# Espressif register map
File version: 1.0
CPU: Xtensa LX6 1, little endian, no MPU, FPU, 3 interrupt priority bits
Registers are 32-bit, access not given, reset 0x0 unless marked. A register's access mark holds for its fields unless they carry their own. Offsets are from the block's base; lines under a group give offsets from that group; [hi:lo] are bit positions; {n}, {i} and the like mark numbered series; 'fields as' and 'values as' point back to an identical list; <NAME> marks a mode.

## Memory map
0x00000000 SPI size 0x860
0x00000000 I2C size 0x4C0
0x00000000 UHCI size 0x620
0x00000000 TIMG size 0x580
0x00000000 MCPWM size 0x940
0x3FF00000 DPORT size 0x2DE0
0x3FF01000 AES
0x3FF02000 RSA
0x3FF03000 SHA
0x3FF40000 UART size 0x3A0
0x3FF42000 SPI1
0x3FF43000 SPI0
0x3FF44000 GPIO size 0x2E60
0x3FF44F00 GPIO_SD size 0x160
0x3FF45000 FE2
0x3FF46000 FE
0x3FF47000 FRC_TIMER
0x3FF48000 RTCCNTL size 0x6A0
0x3FF48400 RTCIO size 0x660
0x3FF48800 SENS size 0x540
0x3FF48C00 RTC_I2C size 0x160
0x3FF49000 IO_MUX
0x3FF4B000 HINF size 0x1A0
0x3FF4C000 UHCI1
0x3FF4F000 I2S size 0x5A0
0x3FF50000 UART1
0x3FF51000 BT
0x3FF53000 I2C_EXT
0x3FF54000 UHCI0
0x3FF55000 SLCHOST size 0x800
0x3FF56000 RMT size 0x6C0
0x3FF57000 PCNT size 0x5C0
0x3FF58000 SLC size 0xA60
0x3FF59000 LEDC size 0xCC0
0x3FF5A000 EFUSE size 0x920
0x3FF5B000 SPI_ENCRYPT
0x3FF5CC00 NRX
0x3FF5D000 BB
0x3FF5E000 PWM
0x3FF5F000 TIMERGROUP0
0x3FF60000 TIMERGROUP1
0x3FF61000 RTCMEM0
0x3FF62000 RTCMEM1
0x3FF63000 RTCMEM2
0x3FF64000 SPI2
0x3FF65000 SPI3
0x3FF66000 APB_CTRL size 0x220
0x3FF66000 SYSCON size 0x220
0x3FF67000 I2C1_EXT
0x3FF68000 SDMMC
0x3FF69000 EMAC
0x3FF6B000 CAN
0x3FF6C000 PWM1
0x3FF6D000 I2S1
0x3FF6E000 UART2
0x3FF6F000 PWM2
0x3FF70000 PWM3

## HINF
Base 0x3FF4B000
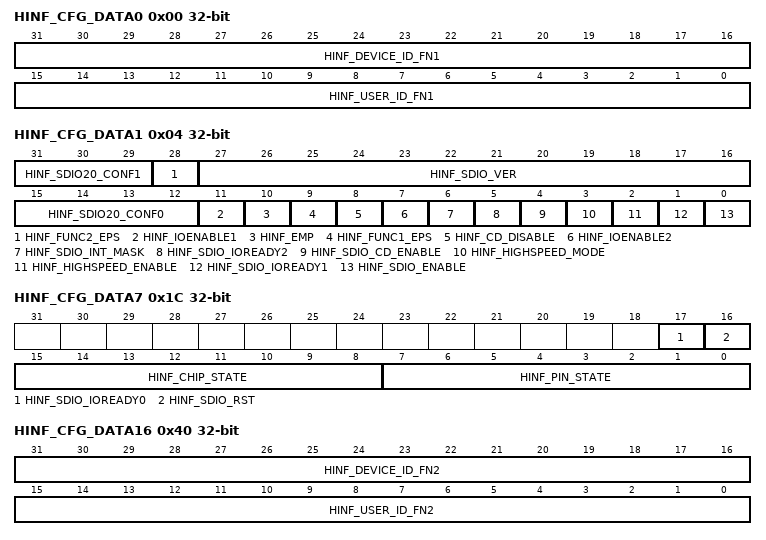
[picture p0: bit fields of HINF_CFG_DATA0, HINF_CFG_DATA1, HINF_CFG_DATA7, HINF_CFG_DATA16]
0x00 HINF_CFG_DATA0
  [31:16] HINF_DEVICE_ID_FN1, [15:0] HINF_USER_ID_FN1
0x04 HINF_CFG_DATA1
  [31:29] HINF_SDIO20_CONF1, [28] HINF_FUNC2_EPS, [27:16] HINF_SDIO_VER, [15:12] HINF_SDIO20_CONF0, [11] HINF_IOENABLE1, [10] HINF_EMP, [9] HINF_FUNC1_EPS, [8] HINF_CD_DISABLE, [7] HINF_IOENABLE2, [6] HINF_SDIO_INT_MASK, [5] HINF_SDIO_IOREADY2, [4] HINF_SDIO_CD_ENABLE, [3] HINF_HIGHSPEED_MODE, [2] HINF_HIGHSPEED_ENABLE, [1] HINF_SDIO_IOREADY1, [0] HINF_SDIO_ENABLE
0x1C HINF_CFG_DATA7
  [17] HINF_SDIO_IOREADY0, [16] HINF_SDIO_RST, [15:8] HINF_CHIP_STATE, [7:0] HINF_PIN_STATE
{0x20+4i} HINF_CIS_CONF{i} (i=0..7)
  [31:0] HINF_CIS_CONF_W{i}
0x40 HINF_CFG_DATA16
  [31:16] HINF_DEVICE_ID_FN2, [15:0] HINF_USER_ID_FN2
0xFC HINF_DATE
  [31:0] HINF_SDIO_DATE

## I2C
Base 0x00000000
0x00 I2C_SCL_LOW_PERIOD
  [13:0] I2C_SCL_LOW_PERIOD
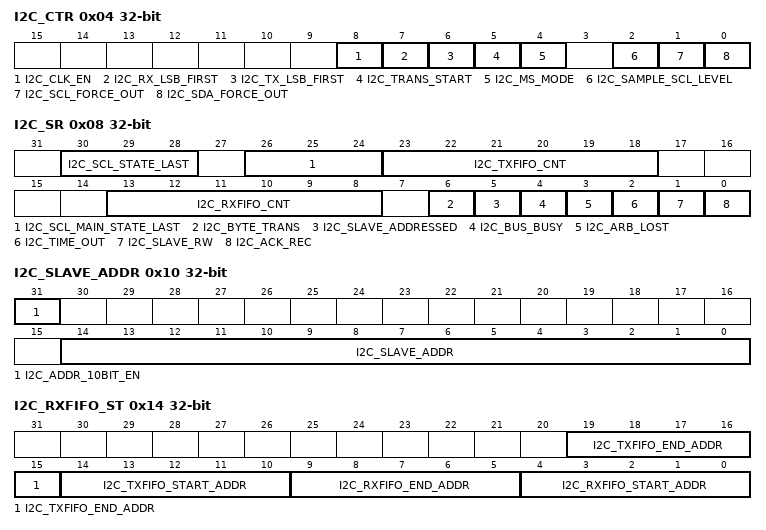
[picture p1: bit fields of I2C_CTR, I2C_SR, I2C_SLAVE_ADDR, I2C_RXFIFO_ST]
0x04 I2C_CTR
  [8] I2C_CLK_EN, [7] I2C_RX_LSB_FIRST, [6] I2C_TX_LSB_FIRST, [5] I2C_TRANS_START, [4] I2C_MS_MODE, [2] I2C_SAMPLE_SCL_LEVEL, [1] I2C_SCL_FORCE_OUT, [0] I2C_SDA_FORCE_OUT
0x08 I2C_SR
  [30:28] I2C_SCL_STATE_LAST, [26:24] I2C_SCL_MAIN_STATE_LAST, [23:18] I2C_TXFIFO_CNT, [13:8] I2C_RXFIFO_CNT, [6] I2C_BYTE_TRANS, [5] I2C_SLAVE_ADDRESSED, [4] I2C_BUS_BUSY, [3] I2C_ARB_LOST, [2] I2C_TIME_OUT, [1] I2C_SLAVE_RW, [0] I2C_ACK_REC
0x0C I2C_TO
  [19:0] I2C_TIME_OUT_REG
0x10 I2C_SLAVE_ADDR
  [31] I2C_ADDR_10BIT_EN, [14:0] I2C_SLAVE_ADDR
0x14 I2C_RXFIFO_ST
  [19:15] I2C_TXFIFO_END_ADDR, [14:10] I2C_TXFIFO_START_ADDR, [9:5] I2C_RXFIFO_END_ADDR, [4:0] I2C_RXFIFO_START_ADDR
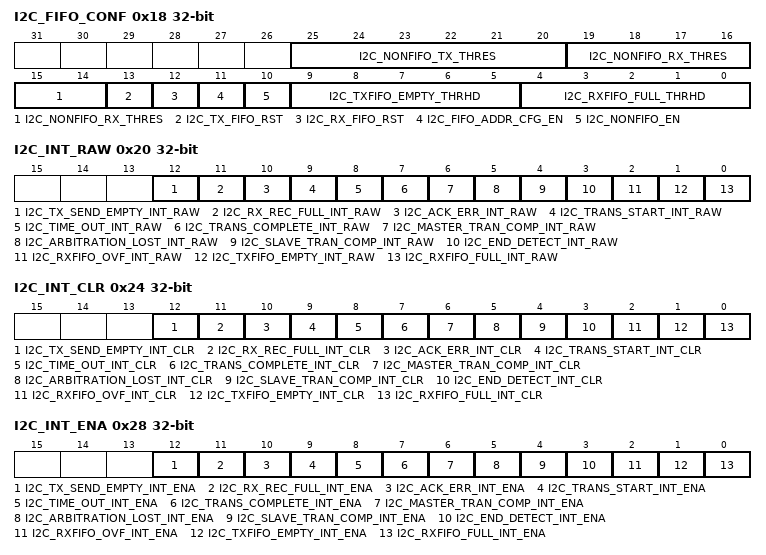
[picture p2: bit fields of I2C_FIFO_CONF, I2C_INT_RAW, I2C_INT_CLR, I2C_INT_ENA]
0x18 I2C_FIFO_CONF
  [25:20] I2C_NONFIFO_TX_THRES, [19:14] I2C_NONFIFO_RX_THRES, [13] I2C_TX_FIFO_RST, [12] I2C_RX_FIFO_RST, [11] I2C_FIFO_ADDR_CFG_EN, [10] I2C_NONFIFO_EN, [9:5] I2C_TXFIFO_EMPTY_THRHD, [4:0] I2C_RXFIFO_FULL_THRHD
0x1C I2C_DATA
  [7:0] I2C_FIFO_RDATA
0x20 I2C_INT_RAW
  [12] I2C_TX_SEND_EMPTY_INT_RAW, [11] I2C_RX_REC_FULL_INT_RAW, [10] I2C_ACK_ERR_INT_RAW, [9] I2C_TRANS_START_INT_RAW, [8] I2C_TIME_OUT_INT_RAW, [7] I2C_TRANS_COMPLETE_INT_RAW, [6] I2C_MASTER_TRAN_COMP_INT_RAW, [5] I2C_ARBITRATION_LOST_INT_RAW, [4] I2C_SLAVE_TRAN_COMP_INT_RAW, [3] I2C_END_DETECT_INT_RAW, [2] I2C_RXFIFO_OVF_INT_RAW, [1] I2C_TXFIFO_EMPTY_INT_RAW, [0] I2C_RXFIFO_FULL_INT_RAW
0x24 I2C_INT_CLR
  [12] I2C_TX_SEND_EMPTY_INT_CLR, [11] I2C_RX_REC_FULL_INT_CLR, [10] I2C_ACK_ERR_INT_CLR, [9] I2C_TRANS_START_INT_CLR, [8] I2C_TIME_OUT_INT_CLR, [7] I2C_TRANS_COMPLETE_INT_CLR, [6] I2C_MASTER_TRAN_COMP_INT_CLR, [5] I2C_ARBITRATION_LOST_INT_CLR, [4] I2C_SLAVE_TRAN_COMP_INT_CLR, [3] I2C_END_DETECT_INT_CLR, [2] I2C_RXFIFO_OVF_INT_CLR, [1] I2C_TXFIFO_EMPTY_INT_CLR, [0] I2C_RXFIFO_FULL_INT_CLR
0x28 I2C_INT_ENA
  [12] I2C_TX_SEND_EMPTY_INT_ENA, [11] I2C_RX_REC_FULL_INT_ENA, [10] I2C_ACK_ERR_INT_ENA, [9] I2C_TRANS_START_INT_ENA, [8] I2C_TIME_OUT_INT_ENA, [7] I2C_TRANS_COMPLETE_INT_ENA, [6] I2C_MASTER_TRAN_COMP_INT_ENA, [5] I2C_ARBITRATION_LOST_INT_ENA, [4] I2C_SLAVE_TRAN_COMP_INT_ENA, [3] I2C_END_DETECT_INT_ENA, [2] I2C_RXFIFO_OVF_INT_ENA, [1] I2C_TXFIFO_EMPTY_INT_ENA, [0] I2C_RXFIFO_FULL_INT_ENA
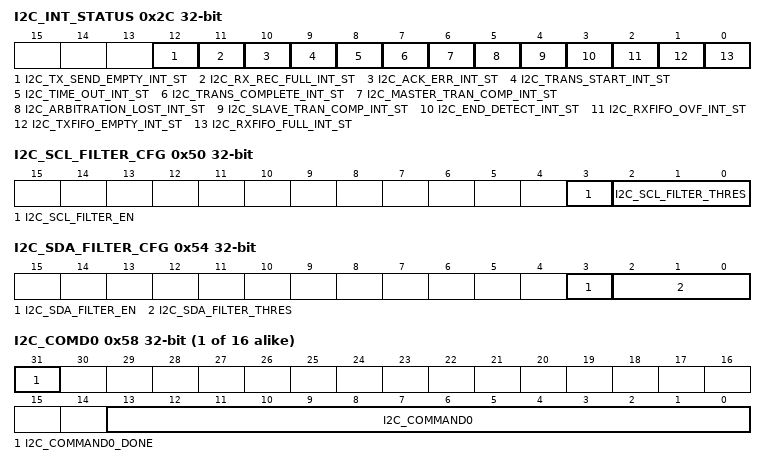
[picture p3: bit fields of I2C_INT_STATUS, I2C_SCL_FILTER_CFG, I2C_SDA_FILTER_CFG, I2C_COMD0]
0x2C I2C_INT_STATUS
  [12] I2C_TX_SEND_EMPTY_INT_ST, [11] I2C_RX_REC_FULL_INT_ST, [10] I2C_ACK_ERR_INT_ST, [9] I2C_TRANS_START_INT_ST, [8] I2C_TIME_OUT_INT_ST, [7] I2C_TRANS_COMPLETE_INT_ST, [6] I2C_MASTER_TRAN_COMP_INT_ST, [5] I2C_ARBITRATION_LOST_INT_ST, [4] I2C_SLAVE_TRAN_COMP_INT_ST, [3] I2C_END_DETECT_INT_ST, [2] I2C_RXFIFO_OVF_INT_ST, [1] I2C_TXFIFO_EMPTY_INT_ST, [0] I2C_RXFIFO_FULL_INT_ST
0x30 I2C_SDA_HOLD
  [9:0] I2C_SDA_HOLD_TIME
0x34 I2C_SDA_SAMPLE
  [9:0] I2C_SDA_SAMPLE_TIME
0x38 I2C_SCL_HIGH_PERIOD
  [13:0] I2C_SCL_HIGH_PERIOD
0x40 I2C_SCL_START_HOLD
  [9:0] I2C_SCL_START_HOLD_TIME
0x44 I2C_SCL_RSTART_SETUP
  [9:0] I2C_SCL_RSTART_SETUP_TIME
0x48 I2C_SCL_STOP_HOLD
  [13:0] I2C_SCL_STOP_HOLD_TIME
0x4C I2C_SCL_STOP_SETUP
  [9:0] I2C_SCL_STOP_SETUP_TIME
0x50 I2C_SCL_FILTER_CFG
  [3] I2C_SCL_FILTER_EN, [2:0] I2C_SCL_FILTER_THRES
0x54 I2C_SDA_FILTER_CFG
  [3] I2C_SDA_FILTER_EN, [2:0] I2C_SDA_FILTER_THRES
{0x58+4i} I2C_COMD{i} (i=0..15)
  [31] I2C_COMMAND{i}_DONE, [13:0] I2C_COMMAND{i}
0xF8 I2C_DATE
